# SCR_TC3xx register map
Vendor: Infineon; File version: 1.0
Registers are 8-bit, read-write, reset 0x0 unless marked. A register's access mark holds for its fields unless they carry their own. Offsets are from the block's base; [hi:lo] are bit positions; {n}, {i} and the like mark numbered series; 'fields as' and 'values as' point back to an identical list.

## SCR_T2CCU — SCR Timer 2 and capture/compare unit
Base 0x00040000
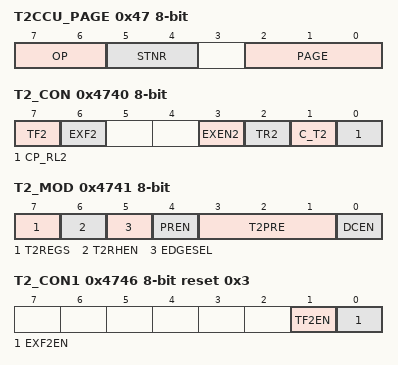
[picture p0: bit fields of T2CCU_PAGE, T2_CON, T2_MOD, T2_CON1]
0x47 T2CCU_PAGE — Page Register for T2CCU (SFR 0xC7, RMAP 0)
  [7:6] OP — Operation. [w]
    0=PAGE_MANUAL0 (Manual page mode. The value of STNR is ignored and PAGE is directly written.); 1=PAGE_MANUAL1 (Manual page mode. The value of STNR is ignored and PAGE is directly written); 2=PAGE_SAVE (New page programming with automatic page saving. The value written to the bit positions of PAGE is stored. In parallel, the former contents of PAGE are saved in the storage bit field STx indicated by STNR.); 3=PAGE_RESTORE (Automatic restore page action. The value written to the bit positions PAGE is ignored and instead, PAGE is overwritten by the contents of the storage bit field STx indicated by STNR.)
  [5:4] STNR — Storage Number. This number indicates which storage bitfield is the target of the operation defined by bit OP. If OP = 10B, the contents of PAGE are saved in STx before being overwritten with the new value. If OP = 11B, the contents of PAGE are overwritten by the contents of STx. The value written to bitfield PAGE is ignored. [w]
    {v}=MOD_ST{v} (ST{v} is selected) (v=0..3)
  [2:0] PAGE — Page Bits. When written, the value indicates the new page address. When read, the value indicates the currently active page = addr[y:x+1]. [rw]
    {v}=Selection is PAGE{v} (v=0..7)
0x4740 T2_CON — Timer 2 Control Register (SFR 0xC0, T2CCU_PAGE page 0, RMAP 0)
  [7] TF2 — Timer 2 Overflow/Underflow Flag. Set by a Timer 2 overflow/underflow. Must be cleared by software. [rwh]
  [6] EXF2 — Timer 2 External Flag. In Capture/Reload Mode, this bit is set by hardware when a negative/positive transition occurs at pin T2EX, if bit EXEN2 = 1. This bit must be cleared by software. Note:When bit DCEN = 1 in auto-reload mode, no interrupt request to the core is generated. [rwh]
  [3] EXEN2 — Timer 2 External Enable Control. [rw]
    0=EXTERNAL_EVENTS_ARE_DISABLED; 1=EXTERNAL_EVENTS_ARE_ENABLED_IN (External events are enabled in Capture/Reload Mode)
  [2] TR2 — Timer 2 Run Control. This bit can be set or cleared by software to start or stop the timer T2. It can also be set by hardware via input T2EX, if bit T2MOD.T2RHEN is set to 1, or via a synchronized start with the CCT timer of the T2CCU. Note:Writing a one to this bit while the timer is running has no effect. [rwh]
    0=TIMER_T2_IS_HALTED; 1=TIMER_T2_IS_RUNNING
  [1] C_T2 — Timer or Counter Select. [rw]
    0=TIMER_FUNCTION_SELECTED; 1=COUNT_UPON_NEGATIVE_EDGE_AT_PIN (Count upon negative edge at pin T2)
  [0] CP_RL2 — Capture/Reload Select. [rw]
    0=RELOAD_UPON_OVERFLOW_OR_UPON (Reload upon overflow or upon negative/positive transition at pin T2EX (when EXEN2 = 1)); 1=CAPTURE_TIMER_2_DATA_REGISTER (Capture Timer 2 data register contents on the negative/positive transition at pin T2EX, provided EXEN2 = 1. The negative or positive transition at pin T2EX is selected by bit EDGESEL in register T2MOD.)
0x4741 T2_MOD — Timer 2 Mode Register (SFR 0xC1, T2CCU_PAGE page 0, RMAP 0)
  [7] T2REGS — Edge Select for Timer 2 External Start. [rw]
    0=THE_FALLING_EDGE_AT_PIN_T2EX_IS (The falling edge at pin T2EX is selected); 1=THE_RISING_EDGE_AT_PIN_T2EX_IS (The rising edge at Pin T2EX is selected)
  [6] T2RHEN — Timer 2 External Start Enable. [rw]
    0=TIMER_2_EXTERNAL_START_IS (Timer 2 External Start is disabled); 1=TIMER_2_EXTERNAL_START_IS_ENABLED
  [5] EDGESEL — Edge Select in Capture Mode/Reload Mode. [rw]
    0=THE_FALLING_EDGE_AT_PIN_T2EX_IS (The falling edge at pin T2EX is selected); 1=THE_RISING_EDGE_AT_PIN_T2EX_IS (The rising edge at pin T2EX is selected)
  [4] PREN — Prescaler Enable. [rw]
    0=PRESCALER_IS_DISABLED_AND_THE_2 (Prescaler is disabled, and the 2 or 12 divider takes effect); 1=PRESCALER_IS_ENABLED_SEE_T2PRE (Prescaler is enabled (see T2PRE bit), and the 2 or 12 divider is bypassed)
  [3:1] T2PRE — Timer 2 Prescaler Bit. Selects the input clock for Timer 2 which is derived from the peripheral clock. [rw]
    0=PCLK (fT2 = fPCLK); 1=PCLK_DIV2 (fT2 = fPCLK / 2); 2=PCLK_DIV4 (fT2 = fPCLK / 4); 3=PCLK_DIV8 (fT2 = fPCLK / 8); 4=PCLK_DIV16 (fT2 = fPCLK / 16); 5=PCLK_DIV32 (fT2 = fPCLK / 32); 6=PCLK_DIV64 (fT2 = fPCLK / 64); 7=PCLK_DIV128 (fT2 = fPCLK / 128)
  [0] DCEN — Up/Down Counter Enable. [rw]
    0=UP_DOWN_COUNTER_FUNCTION_IS (Up/Down Counter function is disabled); 1=UP_DOWN_COUNTER_FUNCTION_IS_2 (Up/Down Counter function is enabled and controlled by pin T2EX (Up = 1, Down = 0))
0x4742 T2_RC2L — Timer 2 Reload/Capture Register, Low Byte (SFR 0xC2, T2CCU_PAGE page 0, RMAP 0)
  [7:0] RC2 — Reload/Capture Value [7:0]. If T2_CON.CP_RL2 = 0, these contents are loaded into the timer register upon an overflow condition. If T2_CON.CP_RL2 = 1, this register is loaded with the current timer count upon a negative/positive transition at pin T2EX when EXEN2 = 1. [rwh]
0x4743 T2_RC2H — Timer 2 Reload/Capture Register, High Byte (SFR 0xC3, T2CCU_PAGE page 0, RMAP 0)
  [7:0] RC2 — Reload/Capture Value [15:8]. If T2_CON.CP_RL2 = 0, these contents are loaded into the timer register upon an overflow condition. If T2_CON.CP_RL2 = 1, this register is loaded with the current timer count upon a negative/positive transition at pin T2EX when EXEN2 = 1. [rwh]
0x4744 T2_T2L — Timer 2, Low Byte (SFR 0xC4, T2CCU_PAGE page 0, RMAP 0)
  [7:0] THL2 — Timer 2 Value [7:0]. These bits indicate the lower 8 bits of the current 16-bit timer value. [rwh]
0x4745 T2_T2H — Timer 2, High Byte (SFR 0xC5, T2CCU_PAGE page 0, RMAP 0)
  [7:0] THL2 — Timer 2 Value [15:8]. These bits indicate the upper 8 bits of the current 16-bit timer value. [rwh]
0x4746 T2_CON1 reset 0x3 — Timer 2 Control Register 1 (SFR 0xC6, T2CCU_PAGE page 0, RMAP 0)
  [1] TF2EN — Overflow/Underflow Interrupt Enable. [rw]
    0=OVERFLOW_UNDERFLOW_INTERRUPT_IS (Overflow/underflow interrupt is disabled); 1=OVERFLOW_UNDERFLOW_INTERRUPT_IS_2 (Overflow/underflow interrupt is enabled)
  [0] EXF2EN — External Interrupt Enable. [rw]
    0=EXTERNAL_INTERRUPT_IS_DISABLED; 1=EXTERNAL_INTERRUPT_IS_ENABLED
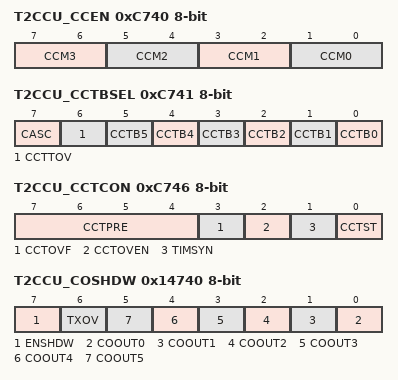
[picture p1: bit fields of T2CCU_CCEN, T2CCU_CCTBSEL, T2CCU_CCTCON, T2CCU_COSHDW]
0xC740 T2CCU_CCEN — T2CCU Capture/Compare Enable Register (SFR 0xC0, T2CCU_PAGE page 1, RMAP 0)
  [7:6] CCM3 — Capture/Compare Enable for Channel 3. [rw]
    0=CC_DIS (Capture/Compare disabled); 1=CAPTURE_ACT_EDGE (Capture on active edge at pin T2CC3); 2=COMP_EN (Compare enabled); 3=CAPTURE_ON_WRITE (Capture on write operation into register CC3L)
  [5:4] CCM2 — Capture/Compare Enable for Channel 2. [rw]
    0=CC_DIS (Capture/Compare disabled); 1=CAPTURE_ACT_EDGE (Capture on active bedge at pin T2CC2); 2=COMP_EN (Compare enabled); 3=CAPTURE_ON_WRITE (Capture on write operation into register CC2L)
  [3:2] CCM1 — Capture/Compare Enable for Channel 1. [rw]
    0=CC_DIS (Capture/Compare disabled); 1=CAPTURE_ACT_EDGE (Capture on active edge at pin T2CC1); 2=COMP_EN (Compare enabled); 3=CAPTURE_ON_WRITE (Capture on write operation into register CC1L)
  [1:0] CCM0 — Capture/Compare Enable for Channel 0. [rw]
    0=CC_DIS (Capture/Compare disabled); 1=CAPTURE_ACT_EDGE (Capture on active edge at pin T2CC0); 2=COMP_EN (Compare enabled); 3=CAPTURE_ON_WRITE (Capture on write operation into register CC0L)
0xC741 T2CCU_CCTBSEL — T2CCU Capture/Compare Time Base Select Register (SFR 0xC1, T2CCU_PAGE page 1, RMAP 0)
  [7] CASC — Cascade Timers. [rw]
    0=TIMER_2_AND_CCT_TIMER_OPERATE (Timer 2 and CCT timer operate independently); 1=TIMER_2_IS_CASCADED_WITH_CCT (Timer 2 is cascaded with CCT timer)
  [6] CCTTOV — Trigger CCT Timer Overflow Event. On set, this bit is held for one PCLK, then cleared by hardware. Reading this bit always returns 0. [rwh]
    0=NO_ACTION; 1=CCT_OVERFLOW_EVENT_IS_TRIGGERED (CCT overflow event is triggered immediately)
  [n] CCTB{n} (n=0..5) — Channel {n} Time Base Select. [rw]
    0=SELECTS_TIMER_2; 1=SELECTS_CAPTURE_COMPARE_TIMER_CCT
0xC742 T2CCU_CCTRELL — T2CCU Capture/Compare Timer Reload Register Low (SFR 0xC2, T2CCU_PAGE page 1, RMAP 0)
  [7:0] CCTREL — Capture/Compare Timer Low Byte Reload Value [7:0]. The contents of the registers are loaded into the CCT timer low byte register upon an overflow condition. [rw]
0xC743 T2CCU_CCTRELH — T2CCU Capture/Compare Timer Reload Register High (SFR 0xC3, T2CCU_PAGE page 1, RMAP 0)
  [7:0] CCTREL — Capture/Compare Timer High Byte Reload Value [15:8]. The contents of the registers are loaded into the CCT timer high byte register upon an overflow condition. [rw]
0xC744 T2CCU_CCTL — T2CCU Capture/Compare Timer Register Low (SFR 0xC4, T2CCU_PAGE page 1, RMAP 0)
  [7:0] CCT — Capture/Compare Timer Low Byte Value [7:0]. The register represents the low byte counter value of the Capture/Compare Timer. When CCT is not running, a write to CCTL updates the lower byte of timer. To (re-)initialize CCT when it is running, CCTH has to be written first. On write to CCTL, the values CCTH and CCTL will be updated to the timer, which then counts from this value. [rwh]
0xC745 T2CCU_CCTH — T2CCU Capture/Compare Timer Register High (SFR 0xC5, T2CCU_PAGE page 1, RMAP 0)
  [7:0] CCT — Capture/Compare Timer High Byte Value [15:8]. The register represents the high byte counter value of the Capture/Compare Timer. When CCT is not running, a write to CCTH updates the upper byte of timer. To (re-)initialize CCT when it is running, CCTH has to be written first. On write to CCTL, the values CCTH and CCTL will be updated to the timer, which then counts from this value. [rwh]
0xC746 T2CCU_CCTCON — T2CCU Capture/Compare Timer Control Register (SFR 0xC6, T2CCU_PAGE page 1, RMAP 0)
  [7:4] CCTPRE — Compare/Compare Timer Prescaler Bitfield. Selects the input clock for CCT, which is derived from the peripheral clock. Note:It is not recommended to change CCTPRE when CCTST = 1. [rw]
    0=DIV (fCCT = fPCLK); 1=DIV2 (fCCT = fPCLK / 2); 2=DIV4 (fCCT = fPCLK / 4); 3=DIV8 (fCCT = fPCLK / 8); 4=DIV16 (fCCT = fPCLK / 16); 5=DIV32 (fCCT = fPCLK / 32); 6=DIV64 (fCCT = fPCLK / 64); 7=DIV128 (fCCT = fPCLK / 128); 8=DIV256 (fCCT = fPCLK / 256); 9=DIV512 (fCCT = fPCLK / 512); 10=DIV1024 (fCCT = fPCLK / 1024); 11=DIV2048 (fCCT = fPCLK / 2048)
  [3] CCTOVF — Capture/Compare Timer Overflow Flag. Set by hardware on CCT overflow. This bit has to be cleared by software. Note:In case of software and hardware access to the flag at the same time, hardware will have higher priority. [rwh]
  [2] CCTOVEN — Capture/Compare Timer Overflow Interrupt Enable. Set to enable CCT overflow interrupt. [rw]
  [1] TIMSYN — Enable Synchronized Timer Starts. [rw]
    0=DISABLE_SYNCHRONIZED_TIMER_STARTS; 1=ENABLE_SYNCHRONIZED_TIMER_STARTS
  [0] CCTST — Capture/Compare Timer Start/Stop Control. Note:Setting CCTST while the bit was already set will not disturb the running CCT timer operation. [rw]
    0=STOP_CAPTURE_COMPARE_TIMER; 1=START_CAPTURE_COMPARE_TIMER_IF (Start Capture/Compare Timer. If bit TIMSYN = 1 and CCTST was 0, start also Timer 2 (if it was not already running).)
0x14740 T2CCU_COSHDW — T2CCU Compare Shadow Register (SFR 0xC0, T2CCU_PAGE page 2, RMAP 0)
  [7] ENSHDW — Enable Shadow Transfer With COOUTx. Clear to enable access of the internal compare output register via the COOUTx bits. Set to enable use of COOUTx bits for transfer of shadow value in T2CCU_CCx to the corresponding channel x internal compare register. Note:When setting bit TXOV, bit ENSHDW will be cleared by internal hardware. To ensure bit ENSHDW is set, user must ensure bit TXOV is cleared. [rwh]
  [6] TXOV — Enable Shadow Transfer On Timer Overflow. Set to enable for all compare channels, transfer of shadow value in T2CCU_CCx to the corresponding internal compare registers on overflow of their respective timer base. [rw]
  [n] COOUT{n} (n=0..5) — Compare Channel {n} Output. ENSHDW = 0: Any access to bit COOUTx accesses the corresponding bit of the internal 6-bit compare output register. Writing to bit COOUTx will change the corresponding bit of the internal compare output register. Reading from bit COOUTx returns the value of the bit in the internal compare output register. The content of the internal compare output register is output on the corresponding T2CCx pins when a valid compare match occurs for a channel in compare mode 1 or concurrent compare mode. Note:A concurrent write operation to clear bit ENSHDW and set/clear bit(s) COOUTx is effective for initializing the internal compare output register. ENSHDW = 1: In this case, accessing bit COOUTx accesses the actual SFR bits. If COOUTx is set, the contents of register CCx will be transferred to corresponding channel x internal compare register. On set, COOUTx is held for one PCLK, then cleared automatically by hardware. Note:A concurrent write operation to set bit ENSHDW and bit(s) COOUTx (and clear bit TXOV) is effective for starting shadow transfer(s). [rwh]
{0x14741+2i} T2CCU_CC{i}L (i=0..2) — T2CCU Capture/Compare Register {i} Low (SFR {0xC1+2i}, T2CCU_PAGE page 2, RMAP 0)
  [7:0] CCVALL — Capture/Compare Low Byte Value for Channel x. Capture: On read, CCVALL returns the low byte of the last captured value. Compare: CCVALL holds the low byte written. CCx acts as a shadow register to the channel x internal compare register. The value written is only transferred to the internal compare register when the corresponding bit T2CCU_COSHDW.COOUTx is being set (with ENSHDW = 1), or on overflow of the channel timer base. The read value always return the last written value. [rwh]
{0x14742+2i} T2CCU_CC{i}H (i=0..2) — T2CCU Capture/Compare Register {i} High (SFR {0xC2+2i}, T2CCU_PAGE page 2, RMAP 0)
  [7:0] CCVALH — Capture/Compare High Byte Value for Channel x. Capture: On read, CCVALH returns the high byte of the last captured value. Compare: CCVALH holds the high byte written. CCx acts as a shadow register to the channel x internal compare register. The value written is only transferred to the internal compare register when the corresponding bit T2CCU_COSHDW.COOUTx is being set (with ENSHDW = 1), or on overflow of the channel timer base. The read value always return the last written value. [rwh]
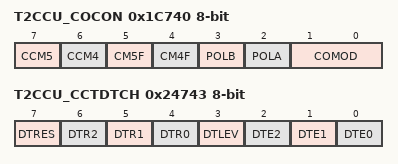
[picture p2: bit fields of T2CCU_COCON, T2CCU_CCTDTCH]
0x1C740 T2CCU_COCON — T2CCU Compare Control Register (SFR 0xC0, T2CCU_PAGE page 3, RMAP 0)
  [7] CCM5 — Compare Enable for Channel 5. Note:Compare channels 4 and 5 should be enabled in a separate step after setting the compare mode via bits COMOD (and active level POLA/B if compare mode 0). This is to ensure defined compare output according to the selected mode on starting the respective compare channel. Note:The interrupt enable for compare channel 5 is controlled by the respective bit of SCU SFR MODIEN.CM5EN. [rw]
    0=COMPARE_DISABLED; 1=COMPARE_ENABLED
  [6] CCM4 — Compare Enable for Channel 4. Note:Compare channels 4 and 5 should be enabled in a separate step after setting the compare mode via bits COMOD (and active level POLA/B if compare mode 0). This is to ensure defined compare output according to the selected mode on starting the respective compare channel. Note:The interrupt enable for compare channel 4 is controlled by the respective bit of SCU SFR MODIEN.CM4EN. [rw]
    0=COMPARE_DISABLED; 1=COMPARE_ENABLED
  [5] CM5F — Compare Channel 5 Interrupt Flag. Set on a compare match event on compare channel 5. This bit has to be cleared by software. Note:In case of software and hardware access to a flag bit at the same time, hardware will have higher priority. [rwh]
  [4] CM4F — Compare Channel 4 Interrupt Flag. Set on a compare match event on compare channel 4. This bit has to be cleared by software. Note:In case of software and hardware access to a flag bit at the same time, hardware will have higher priority. [rwh]
  [3] POLB — Compare Active Level for Channel Group B. In compare mode 0, the bit defines the active level of the outputs of the compare channels belonging to the group. [rw]
    0=HIGH_ON_COMPARE_MATCH; 1=LOW_ON_COMPARE_MATCH
  [2] POLA — Compare Active Level for Channel Group A. In compare mode 0, the bit defines the active level of the outputs of the compare channels belonging to the group. [rw]
    0=HIGH_ON_COMPARE_MATCH; 1=LOW_ON_COMPARE_MATCH
  [1:0] COMOD — Compare Mode Control (for compare channels). [rw]
    0=COMPARE_MODE_0_SELECTED; 1=COMPARE_MODE_1_SELECTED; 2=CONCURRENT_COMPARE_MODE_SELECTED
{0x1C73B+2i} T2CCU_CC{i}L (i=3..5) — T2CCU Capture/Compare Register {i} Low (SFR {0xBB+2i}, T2CCU_PAGE page 3, RMAP 0)
  [7:0] CCVALL — Capture/Compare Low Byte Value for Channel x. Capture: On read, CCVALL returns the low byte of the last captured value. Compare: CCVALL holds the low byte written. CCx acts as a shadow register to the channel x internal compare register. The value written is only transferred to the internal compare register when the corresponding bit T2CCU_COSHDW.COOUTx is being set (with ENSHDW = 1), or on overflow of the channel timer base. The read value always return the last written value. Note:For T2CCU_CC4L/H and T2CCU_CC5L/H, only the compare function is available. [rwh]
{0x1C73C+2i} T2CCU_CC{i}H (i=3..5) — T2CCU Capture/Compare Register {i} High (SFR {0xBC+2i}, T2CCU_PAGE page 3, RMAP 0)
  [7:0] CCVALH — Capture/Compare High Byte Value for Channel x. Capture: On read, CCVALH returns the high byte of the last captured value. Compare: CCVALH holds the high byte written. CCx acts as a shadow register to the channel x internal compare register. The value written is only transferred to the internal compare register when the corresponding bit T2CCU_COSHDW.COOUTx is being set (with ENSHDW = 1), or on overflow of the channel timer base. The read value always return the last written value. Note:For T2CCU_CC4L/H and T2CCU_CC5L/H, only the compare function is available. [rwh]
0x24742 T2CCU_CCTDTCL — T2CCU Capture/Compare Timer Dead-Time Control Register Low (SFR 0xC2, T2CCU_PAGE page 4, RMAP 0)
  [7:0] DTM — Dead-Time Value. This 8-bit value defines the programmable delay between switching from the passive state to the active state of the selected outputs. The switching from the active state to the passive state is not delayed. [rw]
0x24743 T2CCU_CCTDTCH — T2CCU Capture/Compare Timer Dead-Time Control Register High (SFR 0xC3, T2CCU_PAGE page 4, RMAP 0)
  [7] DTRES — Reset Dead-Time Counters. On set, this bit is held for one PCLK, then cleared by hardware. Reading this bit always returns 0. [rwh]
    0=NO_ACTION; 1=THE_THREE_DEAD_TIME_COUNTERS_ARE (The three dead-time counters are reset to 0)
  [6] DTR2 ro — Dead-Time Run Indication Bits. [rh]
    0=THE_VALUE_OF_THE_CORRESPONDING (The value of the corresponding dead-time counter is 0); 1=THE_VALUE_OF_THE_CORRESPONDING_2 (The value of the corresponding dead-time counter is not 0)
  [5] DTR1 ro — Dead-Time Run Indication Bits. [rh]
    values as DTR2
  [4] DTR0 ro — Dead-Time Run Indication Bits. [rh]
    values as DTR2
  [3] DTLEV — Dead-Time Level. This bit defines the active level of all DTCx during dead-time counting. [rw]
    0=LOW_SWITCHES_ARE_ACTIVE_HIGH; 1=HIGH_SWITCHES_ARE_ACTIVE_LOW
  [2] DTE2 — Dead-Time Enable for Channel Pair 2. Note:This bit shall only be set after enabling the corresponding channels in compare mode 0 with CCT timer as the time base. [rw]
    0=DEAD_TIME_GENERATION_IS_DISABLED; 1=DEAD_TIME_GENERATION_IS_ENABLED (Dead-time generation is enabled for channel pair x. The corresponding outputs switch from the passive state to the active state (according to compare status) with the delay programmed in DTM.)
  [1] DTE1 — Dead-Time Enable for Channel Pair 1. Note:This bit shall only be set after enabling the corresponding channels in compare mode 0 with CCT timer as the time base. [rw]
    values as DTE2
  [0] DTE0 — Dead-Time Enable for Channel Pair 0. Note:This bit shall only be set after enabling the corresponding channels in compare mode 0 with CCT timer as the time base. [rw]
    values as DTE2
